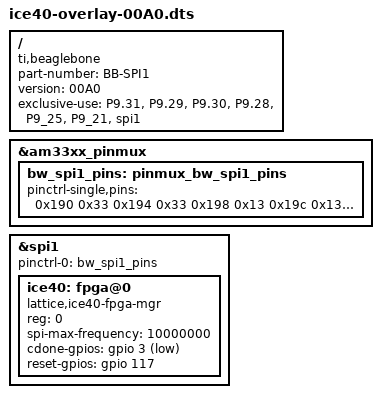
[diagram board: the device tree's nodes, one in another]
/dts-v1/;
/plugin/;

/ {
	compatible = "ti,beaglebone", "ti,beaglebone-black";
	part-number = "BB-SPI1";
	version = "00A0";

	/* state the resources this cape uses */
	exclusive-use =
		/* the pin header uses */
		"P9.31",	/* bw_spi1_sclk */
		"P9.29",	/* bw_spi1_d0 */
		"P9.30",	/* bw_spi1_d1 */
		"P9.28",	/* bw_spi1_cs0 */
		"P9_25",	/* bw_creset */
		"P9_21",	/* bw_cdone */
		"spi1";

	fragment@0 {
		target = <&am33xx_pinmux>;
		__overlay__ {
			bw_spi1_pins: pinmux_bw_spi1_pins {
				pinctrl-single,pins = <
					0x190 0x33	/* mcasp0_aclkx.spi1_sclk, INPUT_PULLUP | MODE3 */
					0x194 0x33	/* mcasp0_fsx.spi1_d0, INPUT_PULLUP | MODE3 */
					0x198 0x13	/* mcasp0_axr0.spi1_d1, OUTPUT_PULLUP | MODE3 */
					0x19c 0x13	/* mcasp0_ahclkr.spi1_cs0, OUTPUT_PULLUP | MODE3 */
					0x1ac 0x07	/* CRESET GPIO OUTPUT | MODE7 */
					0x154 0x27	/* CDONE GPIO INPUT | MODE7 */
				>;
			};
		};
	};

	fragment@1 {
		target = <&spi1>;
		__overlay__ {
			status = "okay";
			pinctrl-names = "default";
			pinctrl-0 = <&bw_spi1_pins>;

			#address-cells = <1>;
			#size-cells = <0>;

			ice40: fpga@0 {
				compatible = "lattice,ice40-fpga-mgr";
				reg = <0>;
				spi-max-frequency = <10000000>;
				cdone-gpios = <&gpio 3 1>;
				reset-gpios = <&gpio 117 0>;
			};	
		};
	};
};
